AUTOSAR XML (schema 4.0)
standard types defined: float32, float64, sint16, sint32, sint8, uint16, uint32, uint8, void, boolean
package /ImplDataTypes
  7 x impl type, all with category=TYPE_REFERENCE, type-emitter=RTE:
    IOPositionSensorReadingType: implementation-data-type=sint8
    IoWeightSensorReadingType: implementation-data-type=uint16
    MultiStateBtnType: implementation-data-type=uint8
    SeatModeBtnType: implementation-data-type=uint8
    SensorPositionType: implementation-data-type=sint8
    SensorWeightType: implementation-data-type=sint8
    StepMotorStepType: implementation-data-type=sint8
package /MappingSets
  data type mapping set MappingSet: mode-request-type-map{implementation-data-type=uint8, mode-group=SeatCtrlMode}
package /PortInterfaces/ClientServer
  6 x client server interface:
    CsIf_IOGetSensorPosition
      operation IOGet
        arg position: type=IOPositionSensorReadingType, direction=OUT
    CsIf_IoGetSensorWeight
      operation IOGet
        arg Weight: type=IoWeightSensorReadingType, direction=OUT
    CsIf_IoSetMotor
      operation IOSetForward
      operation IOSetReverse
    CsIf_PositionSensor
      operation GetPosition
        arg Position: type=SensorPositionType, direction=OUT
    CsIf_StepMotor
      operation Move
        arg step: type=StepMotorStepType, direction=IN
    WeightSensor
      operation GetWeight
        arg weight: type=SensorWeightType, direction=OUT
package /PortInterfaces/ModeSwitch
  mode switch interface MsIf_SeatCtrlMode
    mode group SeatCtrlMode: type=SeatCtrlMode
  mode declaration group SeatCtrlMode: category=ALPHABETIC_ORDER, initial-mode=INIT, on-transition-value=255
    mode Auto
    mode INIT
    mode Manual
package /PortInterfaces/SenderReceiver
  sender receiver interface SrIf_SeatCtrlBtns
    data HeightBtnState: type=MultiStateBtnType
    data InclineBtnState: type=MultiStateBtnType
    data SlideBtnState: type=MultiStateBtnType
  sender receiver interface SrIf_SeatCtrlData
    data Height: type=uint8
    data Incline: type=uint8
    data Slide: type=uint8
  sender receiver interface SrIf_SeatModeBtn
    data SeatModeBtn: type=SeatModeBtnType
package /SoftwareComponents
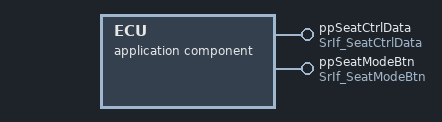
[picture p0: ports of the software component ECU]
  application sw component type ECU
    provide port ppSeatCtrlData: provided-interface=SrIf_SeatCtrlData
    provide port ppSeatModeBtn: provided-interface=SrIf_SeatModeBtn
    behavior Ibhv_ECU: data-type-mapping=MappingSet, handle-termination-and-restart=NO-SUPPORT
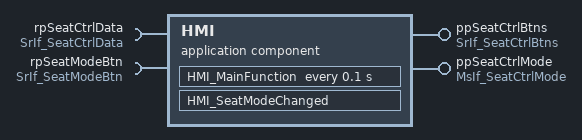
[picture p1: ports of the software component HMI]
  application sw component type HMI
    provide port ppSeatCtrlBtns: provided-interface=SrIf_SeatCtrlBtns
    provide port ppSeatCtrlMode: provided-interface=MsIf_SeatCtrlMode
    require port rpSeatCtrlData: required-interface=SrIf_SeatCtrlData
    require port rpSeatModeBtn: required-interface=SrIf_SeatModeBtn
    behavior Ibhv_HMI: data-type-mapping=MappingSet, handle-termination-and-restart=NO-SUPPORT
      data received event DRE_rpSeatModeBtn_SeatModeBtn: start-on-event=HMI_SeatModeChanged, data=rpSeatModeBtn.SeatModeBtn
      timing event TE_HMI_MainFunction_100ms: start-on-event=HMI_MainFunction, period=0.1
      runnable HMI_MainFunction
        data-receive-point-by-arguments:
          access DRP_rpSeatCtrlData_Height: accessed-variable=rpSeatCtrlData.Height
          access DRP_rpSeatCtrlData_Incline: accessed-variable=rpSeatCtrlData.Incline
          access DRP_rpSeatCtrlData_Slide: accessed-variable=rpSeatCtrlData.Slide
        data-send-points:
          access DSP_ppSeatCtrlBtns_HeightBtnState: accessed-variable=ppSeatCtrlBtns.HeightBtnState
          access DSP_ppSeatCtrlBtns_InclineBtnState: accessed-variable=ppSeatCtrlBtns.InclineBtnState
          access DSP_ppSeatCtrlBtns_SlideBtnState: accessed-variable=ppSeatCtrlBtns.SlideBtnState
      runnable HMI_SeatModeChanged
        data-receive-point-by-arguments:
          access DRP_rpSeatModeBtn_SeatModeBtn: accessed-variable=rpSeatModeBtn.SeatModeBtn
        mode switch point MSP_ppSeatCtrlMode_ppSeatCtrlMode: mode-group=ppSeatCtrlMode.SeatCtrlMode
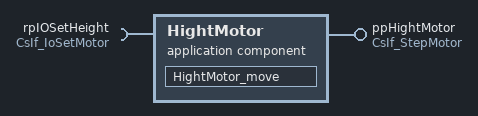
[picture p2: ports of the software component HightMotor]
  application sw component type HightMotor
    provide port ppHightMotor: provided-interface=CsIf_StepMotor
    require port rpIOSetHeight: required-interface=CsIf_IoSetMotor
    behavior Ibhv_HightMotor: data-type-mapping=MappingSet, handle-termination-and-restart=NO-SUPPORT
      operation invoked event OIE_ppHightMotor_Move: start-on-event=HightMotor_move, operation=ppHightMotor.Move
      runnable HightMotor_move
        sync call SCP_rpIOSetHeight_IOSetForward: operation=rpIOSetHeight.IOSetForward, timeout=0.0
        sync call SCP_rpIOSetHeight_IOSetReverse: operation=rpIOSetHeight.IOSetReverse, timeout=0.0
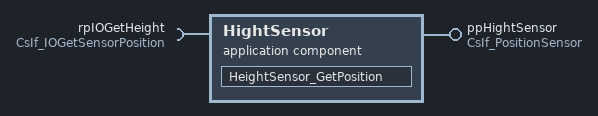
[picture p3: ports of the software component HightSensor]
  application sw component type HightSensor
    provide port ppHightSensor: provided-interface=CsIf_PositionSensor
    require port rpIOGetHeight: required-interface=CsIf_IOGetSensorPosition
    behavior Ibhv_HightSensor: data-type-mapping=MappingSet, handle-termination-and-restart=NO-SUPPORT
      operation invoked event OIE_ppHightSensor_GetPosition: start-on-event=HeightSensor_GetPosition, operation=ppHightSensor.GetPosition
      runnable HeightSensor_GetPosition
        sync call SCP_rpIOGetHeight_IOGet: operation=rpIOGetHeight.IOGet, timeout=0.0
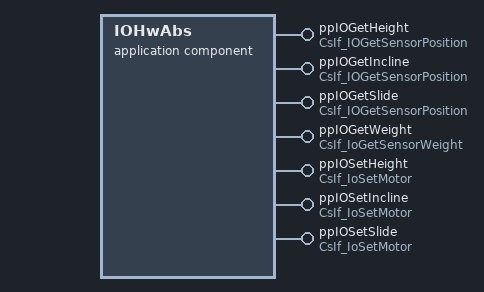
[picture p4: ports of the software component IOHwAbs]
  application sw component type IOHwAbs
    7 x provide port:
      ppIOGetHeight: provided-interface=CsIf_IOGetSensorPosition
      ppIOGetIncline: provided-interface=CsIf_IOGetSensorPosition
      ppIOGetSlide: provided-interface=CsIf_IOGetSensorPosition
      ppIOGetWeight: provided-interface=CsIf_IoGetSensorWeight
      ppIOSetHeight: provided-interface=CsIf_IoSetMotor
      ppIOSetIncline: provided-interface=CsIf_IoSetMotor
      ppIOSetSlide: provided-interface=CsIf_IoSetMotor
    behavior Ibhv_IOHwAbs: data-type-mapping=MappingSet, handle-termination-and-restart=NO-SUPPORT
      10 x operation invoked event:
        OIE_ppIOGetHeight_IOGet: start-on-event=IOHwAbs_ECUGet_Height, operation=ppIOGetHeight.IOGet
        OIE_ppIOGetIncline_IOGet: start-on-event=IOHwAbs_ECUGet_Incline, operation=ppIOGetIncline.IOGet
        OIE_ppIOGetSlide_IOGet: start-on-event=IOHwAbs_ECUGet_Slide, operation=ppIOGetSlide.IOGet
        OIE_ppIOGetWeight_IOGet: start-on-event=IOHwAbs_ECUGet_Weight, operation=ppIOGetWeight.IOGet
        OIE_ppIOSetHeight_IOSetForward: start-on-event=IOHwAbs_ECUSetForward_Height, operation=ppIOSetHeight.IOSetForward
        OIE_ppIOSetHeight_IOSetReverse: start-on-event=IOHwAbs_ECUSetReverse_Height, operation=ppIOSetHeight.IOSetReverse
        OIE_ppIOSetIncline_IOSetForward: start-on-event=IOHwAbs_ECUSetForward_Incline, operation=ppIOSetIncline.IOSetForward
        OIE_ppIOSetIncline_IOSetReverse: start-on-event=IOHwAbs_ECUSetReverse_Incline, operation=ppIOSetIncline.IOSetReverse
        OIE_ppIOSetSlide_IOSetForward: start-on-event=IOHwAbs_ECUSetForward_Slide, operation=ppIOSetSlide.IOSetForward
        OIE_ppIOSetSlide_IOSetReverse: start-on-event=IOHwAbs_ECUSetReverse_Slide, operation=ppIOSetSlide.IOSetReverse
      10 x runnable:
        IOHwAbs_ECUGet_Height
        IOHwAbs_ECUGet_Incline
        IOHwAbs_ECUGet_Slide
        IOHwAbs_ECUGet_Weight
        IOHwAbs_ECUSetForward_Height
        IOHwAbs_ECUSetForward_Incline
        IOHwAbs_ECUSetForward_Slide
        IOHwAbs_ECUSetReverse_Height
        IOHwAbs_ECUSetReverse_Incline
        IOHwAbs_ECUSetReverse_Slide
  11 x swc implementation, all with programming-language=C, sw-version=1.0.0, vendor-id=255:
    Impl_ECU: behavior=Ibhv_ECU
      code-descriptors:
        code Code: artifact-descriptors=autosar-engineering-object={short-label=SWC.c, category=SWSRC}
      resource consumption ResourceConsumption
    Impl_HMI: behavior=Ibhv_HMI
      code-descriptors:
        code Code: artifact-descriptors=autosar-engineering-object={short-label=SWC.c, category=SWSRC}
      resource consumption ResourceConsumption
    Impl_HightMotor: behavior=Ibhv_HightMotor
      code-descriptors:
        code Code: artifact-descriptors=autosar-engineering-object={short-label=SWC.c, category=SWSRC}
      resource consumption ResourceConsumption
    Impl_HightSensor: behavior=Ibhv_HightSensor
      code-descriptors:
        code Code: artifact-descriptors=autosar-engineering-object={short-label=SWC.c, category=SWSRC}
      resource consumption ResourceConsumption
    Impl_IOHwAbs: behavior=Ibhv_IOHwAbs
      code-descriptors:
        code Code: artifact-descriptors=autosar-engineering-object={short-label=SWC.c, category=SWSRC}
      resource consumption ResourceConsumption
    Impl_InclineMotor: behavior=Ibhv_InclineMotor
      code-descriptors:
        code Code: artifact-descriptors=autosar-engineering-object={short-label=SWC.c, category=SWSRC}
      resource consumption ResourceConsumption
    Impl_InclineSensor: behavior=Ibhv_InclineSensor
      code-descriptors:
        code Code: artifact-descriptors=autosar-engineering-object={short-label=SWC.c, category=SWSRC}
      resource consumption ResourceConsumption
    Impl_SeatMgr: behavior=Ibhv_SeatMgr
      code-descriptors:
        code Code: artifact-descriptors=autosar-engineering-object={short-label=SWC.c, category=SWSRC}
      resource consumption ResourceConsumption
    Impl_SlideMotor: behavior=Ibhv_SlideMotor
      code-descriptors:
        code Code: artifact-descriptors=autosar-engineering-object={short-label=SWC.c, category=SWSRC}
      resource consumption ResourceConsumption
    Impl_SlideSensor: behavior=Ibhv_SlideSensor
      code-descriptors:
        code Code: artifact-descriptors=autosar-engineering-object={short-label=SWC.c, category=SWSRC}
      resource consumption ResourceConsumption
    Impl_WeightSensor: behavior=Ibhv_WeightSensor
      code-descriptors:
        code Code: artifact-descriptors=autosar-engineering-object={short-label=SWC.c, category=SWSRC}
      resource consumption ResourceConsumption
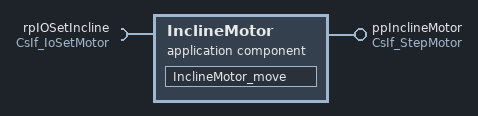
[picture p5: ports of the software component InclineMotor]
  application sw component type InclineMotor
    provide port ppInclineMotor: provided-interface=CsIf_StepMotor
    require port rpIOSetIncline: required-interface=CsIf_IoSetMotor
    behavior Ibhv_InclineMotor: data-type-mapping=MappingSet, handle-termination-and-restart=NO-SUPPORT
      operation invoked event OIE_ppInclineMotor_Move: start-on-event=InclineMotor_move, operation=ppInclineMotor.Move
      runnable InclineMotor_move
        sync call SCP_rpIOSetIncline_IOSetForward: operation=rpIOSetIncline.IOSetForward, timeout=0.0
        sync call SCP_rpIOSetIncline_IOSetReverse: operation=rpIOSetIncline.IOSetReverse, timeout=0.0
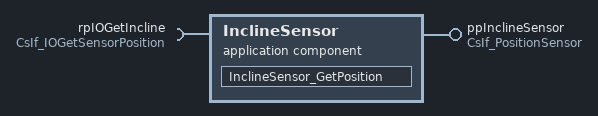
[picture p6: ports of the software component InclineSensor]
  application sw component type InclineSensor
    provide port ppInclineSensor: provided-interface=CsIf_PositionSensor
    require port rpIOGetIncline: required-interface=CsIf_IOGetSensorPosition
    behavior Ibhv_InclineSensor: data-type-mapping=MappingSet, handle-termination-and-restart=NO-SUPPORT
      operation invoked event OIE_ppInclineSensor_GetPosition: start-on-event=InclineSensor_GetPosition, operation=ppInclineSensor.GetPosition
      runnable InclineSensor_GetPosition
        sync call SCP_rpIOGetIncline_IOGet: operation=rpIOGetIncline.IOGet, timeout=0.0
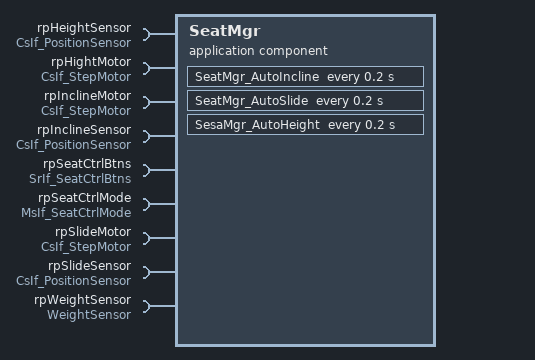
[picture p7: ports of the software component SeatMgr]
  application sw component type SeatMgr
    9 x require port:
      rpHeightSensor: required-interface=CsIf_PositionSensor
      rpHightMotor: required-interface=CsIf_StepMotor
      rpInclineMotor: required-interface=CsIf_StepMotor
      rpInclineSensor: required-interface=CsIf_PositionSensor
      rpSeatCtrlBtns: required-interface=SrIf_SeatCtrlBtns
      rpSeatCtrlMode: required-interface=MsIf_SeatCtrlMode
      rpSlideMotor: required-interface=CsIf_StepMotor
      rpSlideSensor: required-interface=CsIf_PositionSensor
      rpWeightSensor: required-interface=WeightSensor
    behavior Ibhv_SeatMgr: data-type-mapping=MappingSet, handle-termination-and-restart=NO-SUPPORT
      data received event DRE_rpSeatCtrlBtns_HeightBtnState: start-on-event=SeatMgr_SetHeight, data=rpSeatCtrlBtns.HeightBtnState
      data received event DRE_rpSeatCtrlBtns_InclineBtnState: start-on-event=SeatMgr_SetIncline, data=rpSeatCtrlBtns.InclineBtnState
      data received event DRE_rpSeatCtrlBtns_SlideBtnState: start-on-event=SeatMgr_SetSlide, data=rpSeatCtrlBtns.SlideBtnState
      timing event TE_SeatMgr_AutoIncline_200ms: start-on-event=SeatMgr_AutoIncline, period=0.2
      timing event TE_SeatMgr_AutoSlide_200ms: start-on-event=SeatMgr_AutoSlide, period=0.2
      timing event TE_SesaMgr_AutoHeight_200ms: start-on-event=SesaMgr_AutoHeight, period=0.2
      6 x runnable:
        SeatMgr_AutoIncline
          sync call SCP_rpInclineMotor_Move: operation=rpInclineMotor.Move, timeout=0.0
          sync call SCP_rpInclineSensor_GetPosition: operation=rpInclineSensor.GetPosition, timeout=0.0
          sync call SCP_rpWeightSensor_GetWeight: operation=rpWeightSensor.GetWeight, timeout=0.0
        SeatMgr_AutoSlide
          sync call SCP_rpSlideMotor_Move: operation=rpSlideMotor.Move, timeout=0.0
          sync call SCP_rpSlideSensor_GetPosition: operation=rpSlideSensor.GetPosition, timeout=0.0
          sync call SCP_rpWeightSensor_GetWeight: operation=rpWeightSensor.GetWeight, timeout=0.0
        SeatMgr_SetHeight
          data-receive-point-by-arguments:
            access DRP_rpSeatCtrlBtns_HeightBtnState: accessed-variable=rpSeatCtrlBtns.HeightBtnState
          sync call SCP_rpHightMotor_Move: operation=rpHightMotor.Move, timeout=0.0
        SeatMgr_SetIncline
          data-receive-point-by-arguments:
            access DRP_rpSeatCtrlBtns_InclineBtnState: accessed-variable=rpSeatCtrlBtns.InclineBtnState
          sync call SCP_rpInclineMotor_Move: operation=rpInclineMotor.Move, timeout=0.0
        SeatMgr_SetSlide
          data-receive-point-by-arguments:
            access DRP_rpSeatCtrlBtns_SlideBtnState: accessed-variable=rpSeatCtrlBtns.SlideBtnState
          sync call SCP_rpSlideMotor_Move: operation=rpSlideMotor.Move, timeout=0.0
        SesaMgr_AutoHeight
          sync call SCP_rpHeightSensor_GetPosition: operation=rpHeightSensor.GetPosition, timeout=0.0
          sync call SCP_rpHightMotor_Move: operation=rpHightMotor.Move, timeout=0.0
          sync call SCP_rpWeightSensor_GetWeight: operation=rpWeightSensor.GetWeight, timeout=0.0
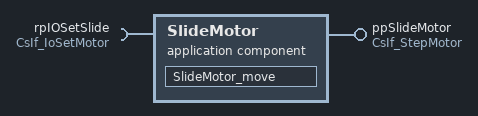
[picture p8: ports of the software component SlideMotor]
  application sw component type SlideMotor
    provide port ppSlideMotor: provided-interface=CsIf_StepMotor
    require port rpIOSetSlide: required-interface=CsIf_IoSetMotor
    behavior Ibhv_SlideMotor: data-type-mapping=MappingSet, handle-termination-and-restart=NO-SUPPORT
      operation invoked event OIE_ppSlideMotor_Move: start-on-event=SlideMotor_move, operation=ppSlideMotor.Move
      runnable SlideMotor_move
        sync call SCP_rpIOSetSlide_IOSetForward: operation=rpIOSetSlide.IOSetForward, timeout=0.0
        sync call SCP_rpIOSetSlide_IOSetReverse: operation=rpIOSetSlide.IOSetReverse, timeout=0.0
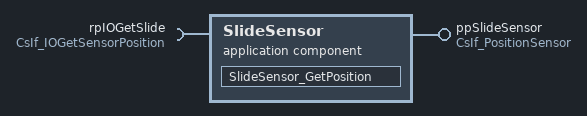
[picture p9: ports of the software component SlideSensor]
  application sw component type SlideSensor
    provide port ppSlideSensor: provided-interface=CsIf_PositionSensor
    require port rpIOGetSlide: required-interface=CsIf_IOGetSensorPosition
    behavior Ibhv_SlideSensor: data-type-mapping=MappingSet, handle-termination-and-restart=NO-SUPPORT
      operation invoked event OIE_ppSlideSensor_GetPosition: start-on-event=SlideSensor_GetPosition, operation=ppSlideSensor.GetPosition
      runnable SlideSensor_GetPosition
        sync call SCP_rpIOGetSlide_IOGet: operation=rpIOGetSlide.IOGet, timeout=0.0
  application sw component type WeightSensor
    provide port ppWeightSensor: provided-interface=WeightSensor
    require port rpIOGetWeight: required-interface=CsIf_IoGetSensorWeight
    behavior Ibhv_WeightSensor: data-type-mapping=MappingSet, handle-termination-and-restart=NO-SUPPORT
      operation invoked event OIE_ppWeightSensor_GetWeight: start-on-event=WeightSensor_GetWieght, operation=ppWeightSensor.GetWeight
      runnable WeightSensor_GetWieght
        sync call SCP_rpIOGetWeight_IOGet: operation=rpIOGetWeight.IOGet, timeout=0.0
package /Compositions
  composition sw component type SeatControllerComposition
    11 x component:
      ECU: type=ECU
      HMI: type=HMI
      HightMotor: type=HightMotor
      HightSensor: type=HightSensor
      IOHwAbs: type=IOHwAbs
      InclineMotor: type=InclineMotor
      InclineSensor: type=InclineSensor
      SeatMgr: type=SeatMgr
      SlideMotor: type=SlideMotor
      SlideSensor: type=SlideSensor
      WeightSensor: type=WeightSensor
    connect ECU.ppSeatCtrlData -> HMI.rpSeatCtrlData
    connect ECU.ppSeatModeBtn -> HMI.rpSeatModeBtn
    connect HMI.ppSeatCtrlBtns -> SeatMgr.rpSeatCtrlBtns
    connect HMI.ppSeatCtrlMode -> SeatMgr.rpSeatCtrlMode
    connect HightMotor.ppHightMotor -> SeatMgr.rpHightMotor
    connect HightSensor.ppHightSensor -> SeatMgr.rpHeightSensor
    connect IOHwAbs.ppIOGetHeight -> HightSensor.rpIOGetHeight
    connect IOHwAbs.ppIOGetIncline -> InclineSensor.rpIOGetIncline
    connect IOHwAbs.ppIOGetSlide -> SlideSensor.rpIOGetSlide
    connect IOHwAbs.ppIOGetWeight -> WeightSensor.rpIOGetWeight
    connect IOHwAbs.ppIOSetHeight -> HightMotor.rpIOSetHeight
    connect IOHwAbs.ppIOSetIncline -> InclineMotor.rpIOSetIncline
    connect IOHwAbs.ppIOSetSlide -> SlideMotor.rpIOSetSlide
    connect InclineMotor.ppInclineMotor -> SeatMgr.rpInclineMotor
    connect InclineSensor.ppInclineSensor -> SeatMgr.rpInclineSensor
    connect SlideMotor.ppSlideMotor -> SeatMgr.rpSlideMotor
    connect SlideSensor.ppSlideSensor -> SeatMgr.rpSlideSensor
    connect WeightSensor.ppWeightSensor -> SeatMgr.rpWeightSensor
